# STM32U3C5xx register map
File version: 1.0
Registers are 32-bit, read-write, reset 0x0 unless marked. A register's access mark holds for its fields unless they carry their own. Offsets are from the block's base; [hi:lo] are bit positions; 'fields as' and 'values as' point back to an identical list.

## RCC — Reset and Clock Control
Base 0x40030C00
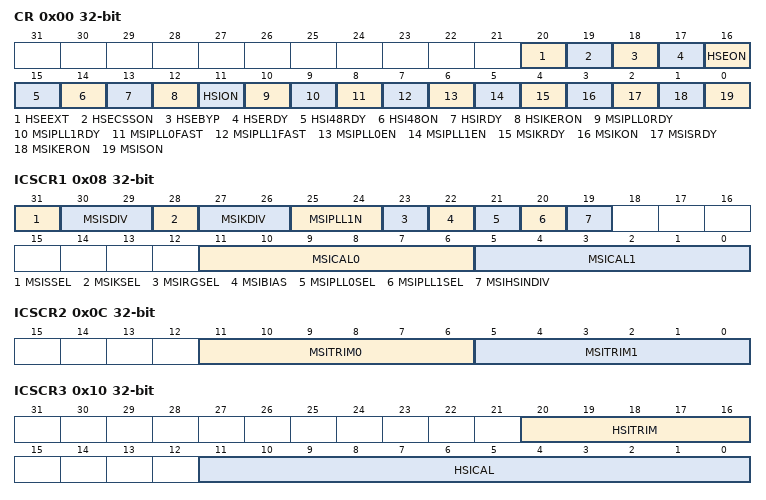
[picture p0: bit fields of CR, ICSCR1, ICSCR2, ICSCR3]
0x00 CR — RCC Clock Control Register
  [20] HSEEXT — External High Speed Oscillator (HSE) External Clock Bypass Mode
    0=ANALOG_MODE; 1=DIGITAL_MODE
  [19] HSECSSON — External High Speed Oscillator (HSE) Clock Security System Enable
  [18] HSEBYP — External High Speed Oscillator (HSE) Crystal Oscillator Bypass
  [17] HSERDY — External High Speed Oscillator (HSE) Clock Ready
  [16] HSEON — External High Speed Oscillator (HSE) Clock Enable
  [15] HSI48RDY — Internal High Speed Oscillator (HSI48) Clock Ready Flag
  [14] HSI48ON — Internal High Speed Oscillator (HSI48) Clock Enable
  [13] HSIRDY — Internal High Speed Oscillator (HSI16) Clock Ready Flag
  [12] HSIKERON — Internal High Speed Oscillator (HSI16) Clock Enable for some peripheral Kernels
  [11] HSION — Internal High Speed Oscillator (HSI16) Clock Enable
  [10] MSIPLL0RDY — MSIRC0 PLL-mode ready flag
  [9] MSIPLL1RDY — MSIRC1 PLL-mode ready flag
  [8] MSIPLL0FAST — MSIRC0 PLL-mode fast startup
    0=NORMAL (MSIRC0 PLL mode normal startup); 1=FAST (MSIRC0 PLL mode fast startup)
  [7] MSIPLL1FAST — MSIRC1 PLL-mode fast startup
    0=NORMAL (MSIRC1 PLL mode normal startup); 1=FAST (MSIRC1 PLL mode fast startup)
  [6] MSIPLL0EN — MSIRC0 PLL-mode enable
  [5] MSIPLL1EN — MSIRC1 PLL-mode enable
  [4] MSIKRDY — Internal Multi Speed Oscillator Kernel (MSIK) Ready Flag
  [3] MSIKON — Internal Multi Speed Oscillator Kernel (MSIK) Enable
  [2] MSISRDY — Internal Multi Speed Oscillator System (MSIS) Clock Ready Flag
  [1] MSIKERON — MSI Enable for some peripheral Kernels
  [0] MSISON — Internal Multi Speed Oscillator System (MSIS) Clock Enable
0x08 ICSCR1 — RCC Internal Clock Sources Calibration Register 1
  [31] MSISSEL — MSIS clock source selection
    0=RC0 (MSIRC0 (96 MHz) is selected as source to generate MSISSRANGE); 1=RC1 (MSIRC1 (24 MHz) is selected as source to generate MSISSRANGE)
  [30:29] MSISDIV — MSIS Oscillator division
    0=DIV_1 (MSIRCx /1 is selected for MSIS (RC0 : range 0 around 96 MHz / RC1 : range 4 around 24 MHz)); 1=DIV_2 (MSIRCx /2 is selected for MSIS (RC0 : range 0 around 48 MHz / RC1 : range 4 around 12 MHz)); 2=DIV_4 (MSIRCx /4 is selected for MSIS (RC0 : range 0 around 24 MHz / RC1 : range 4 around 6 MHz)); 3=DIV_8 (MSIRCx /8 is selected for MSIS (RC0 : range 0 around 12 MHz / RC1 : range 4 around 3 MHz))
  [28] MSIKSEL — MSIK clock source selection
    0=RC0 (MSIRC0 (96 MHz) is selected as source to generate MSIKSRANGE); 1=RC1 (MSIRC1 (24 MHz) is selected as source to generate MSIKSRANGE)
  [27:26] MSIKDIV — MSIK Oscillator division
    0=DIV_1 (MSIRCx /1 is selected for MSIK (RC0 : range 0 around 96 MHz / RC1 : range 4 around 24 MHz)); 1=DIV_2 (MSIRCx /2 is selected for MSIK (RC0 : range 0 around 48 MHz / RC1 : range 4 around 12 MHz)); 2=DIV_4 (MSIRCx /4 is selected for MSIK (RC0 : range 0 around 24 MHz / RC1 : range 4 around 6 MHz)); 3=DIV_8 (MSIRCx /8 is selected for MSIK (RC0 : range 0 around 12 MHz / RC1 : range 4 around 3 MHz))
  [25:24] MSIPLL1N — MSIPLL1N[1:0] bits: MSIRC1 frequency selection in PLL-mode
    0=MULT_732 (Freq MSIRC1 = 23.9862 MHz); 2=MULT_689 (Freq MSIRC1 = 22.5772 MHz); 3=MULT_750 (Freq MSIRC1 = 24.576 MHz)
  [23] MSIRGSEL — MSI clock range selection
    0=MSIXDIVS (MSIS/MSIK ranges provided by MSISSRANGE[3:0] and MSIKSRANGE[3:0] in RCC_CSR); 1=MSIXDIV (MSIS/MSIK ranges provided by MSISRANGE[3:0] and MSIKRANGE[3:0] in RCC_ICSCR1)
  [22] MSIBIAS — MSI BIAS mode selection
    0=CONTINUOUS (MSI bias continuous mode (clock accuracy fast settling time)); 1=SAMPLING (MSI bias sampling mode when the device is in Stop 1 or Stop 2 (ultra-low-power mode))
  [21] MSIPLL0SEL — MSIRC0 PLL-mode input clock Selection
    0=LSE (LSE is used as MSIRC0 input clock when PLL-mode is selected); 1=HSE_OR_HSEDIV2 (HSE or HSE/2 is used as MSIRC0 input clock when PLL-mode is selected)
  [20] MSIPLL1SEL — MSIRC1 PLL-mode input clock Selection
    0=LSE (LSE is used as MSIRC1 input clock when PLL-mode is selected); 1=HSE_OR_HSEDIV2 (HSE or HSE/2 is used as MSIRC1 input clock when PLL-mode is selected)
  [19] MSIHSINDIV — MSIRCx PLL-mode HSE input fast clock Division
    0=HSE (HSE (16 MHz) is used as MSI input clock when PLL-mode with high-speed clock is selected); 1=DIV_2 (HSE (32 MHz) /2 is used as MSI input clock when PLL-mode with high-speed clock is selected)
  [11:6] MSICAL0 — MSICAL0[5:0] bits: MSIRC0 clock Calibration
  [5:0] MSICAL1 — MSICAL1[5:0] bits: MSIRC1 clock Calibration
0x0C ICSCR2 — RCC Internal Clock Sources Calibration Register 2
  [11:6] MSITRIM0 — MSITRIM0[5:0] bits: MSIRC0 clock trimming
  [5:0] MSITRIM1 — MSITRIM1[5:0] bits: MSIRC1 clock trimming
0x10 ICSCR3 — RCC Internal Clock Sources Calibration Register 3
  [20:16] HSITRIM — HSITRIM[4:0] bits: HSI clock trimming
  [11:0] HSICAL — HSICAL[11:0] bits: HSI clock calibration
0x14 CRRCR — RCC Clock Recovery RC Register
  [8:0] HSI48CAL — HSI48CAL[8:0] bits: HSI48 Clock Calibration
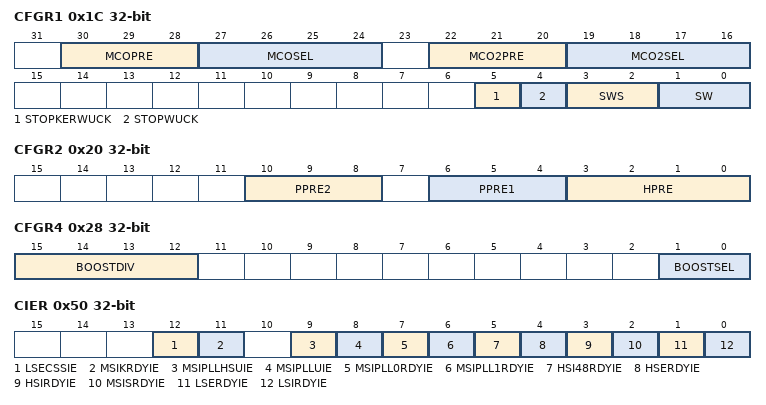
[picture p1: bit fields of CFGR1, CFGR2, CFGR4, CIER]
0x1C CFGR1 — RCC Clock Configuration Register 1
  [30:28] MCOPRE — MCOPRE [2:0] bits : Microcontroller Clock Output (MCO) Prescaler
    0=DIV_1 (MCO not divided); 1=DIV_2 (MCO divided by 2); 2=DIV_4 (MCO divided by 4); 3=DIV_8 (MCO divided by 8); 4=DIV_16 (MCO divided by 16); 5=DIV_32 (MCO divided by 32); 6=DIV_64 (MCO divided by 64); 7=DIV_128 (MCO divided by 128)
  [27:24] MCOSEL — MCOSEL [3:0] bits : Microcontroller Clock Output (MCO) Selection
    0=NOCLOCK (MCO output disabled, no clock on MCO); 1=SYSCLK (SYSCLK selection as MCO source); 2=MSIS (MSIS selection as MCO source); 3=HSI16 (HSI16 selection as MCO source); 4=HSE (HSE selection as MCO source); 5=LSI (LSI selection as MCO source); 6=LSE (LSE selection as MCO source); 7=HSI48 (HSI48 selection as MCO source); 8=MSIK (MSIK selection as MCO source)
  [22:20] MCO2PRE — MCO2PRE [2:0] bits : Microcontroller Clock Output 2 (MCO2) Prescaler
    0=DIV_1 (MCO2 not divided); 1=DIV_2 (MCO2 divided by 2); 2=DIV_4 (MCO2 divided by 4); 3=DIV_8 (MCO2 divided by 8); 4=DIV_16 (MCO2 divided by 16); 5=DIV_32 (MCO2 divided by 32); 6=DIV_64 (MCO2 divided by 64); 7=DIV_128 (MCO2 divided by 128)
  [19:16] MCO2SEL — MCO2SEL [3:0] bits : Microcontroller Clock Output 2 (MCO2) Selection
    0=NOCLOCK (MCO2 output disabled, no clock on MCO2); 1=SYSCLK (SYSCLK selection as MCO2 source); 2=MSIS (MSIS selection as MCO2 source); 3=HSI16 (HSI16 selection as MCO2 source); 4=HSE (HSE selection as MCO2 source); 5=LSI (LSI selection as MCO2 source); 6=LSE (LSE selection as MCO2 source); 7=HSI48 (HSI48 selection as MCO2 source); 8=MSIK (MSIK selection as MCO2 source)
  [5] STOPKERWUCK — Wakeup from Stop kernel clock automatic enable selection
    0=MSIK (MSIK oscillator selected as wakeup from stop kernel clock); 1=HSI16 (HSI16 oscillator selected as wakeup from stop kernel clock)
  [4] STOPWUCK — Wake Up from stop and CSS backup clock selection
    0=MSIS (MSIS oscillator selected as wakeup from stop clock and CSS backup clock); 1=HSI16 (HSI16 oscillator selected as wakeup from stop clock and CSS backup clock)
  [3:2] SWS — SWS[1:0] bits : System Clock Switch Status
  [1:0] SW — SW[1:0] bits : System clock Switch
    0=MSIS (MSIS selection as system clock); 1=HSI16 (HSI16 selection as system clock); 2=HSE (HSE selection as system clock)
0x20 CFGR2 — RCC Clock Configuration Register 2
  [10:8] PPRE2 — PPRE2[2:0] bits : APB2 prescaler
    0=DIV_1 (HCLK not divided); 4=DIV_2 (HCLK divided by 2); 5=DIV_4 (HCLK divided by 4); 6=DIV_8 (HCLK divided by 8); 7=DIV_16 (HCLK divided by 16)
  [6:4] PPRE1 — PPRE1[2:0] bits : APB1 prescaler
    values as PPRE2
  [3:0] HPRE — HPRE[3:0] bits : AHB prescaler
    0=DIV_1 (SYSCLK not divided); 8=DIV_2 (SYSCLK divided by 2); 9=DIV_4 (SYSCLK divided by 4); 10=DIV_8 (SYSCLK divided by 8); 11=DIV_16 (SYSCLK divided by 16); 12=DIV_64 (SYSCLK divided by 64); 13=DIV_128 (SYSCLK divided by 128); 14=DIV_256 (SYSCLK divided by 256); 15=DIV_512 (SYSCLK divided by 512)
0x24 CFGR3 — RCC Clock Configuration Register 3
  [6:4] PPRE3 — PPRE3[2:0] bits : APB3 prescaler
    values as CFGR2.PPRE2
0x28 CFGR4 — RCC Clock Configuration Register 4
  [15:12] BOOSTDIV — BOOSTDIV[3:0] bits : EPOD booster input clock prescaler
    0=EPODBOOSTCLKPRESCAL_1; 1=EPODBOOSTCLKPRESCAL_2; 2=EPODBOOSTCLKPRESCAL_4; 3=EPODBOOSTCLKPRESCAL_6; 4=EPODBOOSTCLKPRESCAL_8; 5=EPODBOOSTCLKPRESCAL_10; 6=EPODBOOSTCLKPRESCAL_12; 7=EPODBOOSTCLKPRESCAL_14; 8=EPODBOOSTCLKPRESCAL_16
  [1:0] BOOSTSEL — BOOSTSEL[1:0] bits : EPOD booster input clock source selection
    0=BYPASS; 1=MSIS; 2=HSI16; 3=HSE
0x50 CIER — Clock Interrupt Enable Register
  [12] LSECSSIE — LSE Clock Security System Interrupt Enable
  [11] MSIKRDYIE — MSIK Ready Interrupt Enable
  [9] MSIPLLHSUIE — MSI PLL-mode with HSE unlock Interrupt Enable
  [8] MSIPLLUIE — MSI PLL-mode with LSE unlock Interrupt Enable
  [7] MSIPLL0RDYIE — MSIRC0 PLL-mode Ready Interrupt Enable
  [6] MSIPLL1RDYIE — MSIRC1 PLL-mode Ready Interrupt Enable
  [5] HSI48RDYIE — HSI48 Ready Interrupt Enable
  [4] HSERDYIE — HSE Ready Interrupt Enable
  [3] HSIRDYIE — HSI16 Ready Interrupt Enable
  [2] MSISRDYIE — MSIS Ready Interrupt Enable
  [1] LSERDYIE — LSE Ready Interrupt Enable
  [0] LSIRDYIE — LSI Ready Interrupt Enable
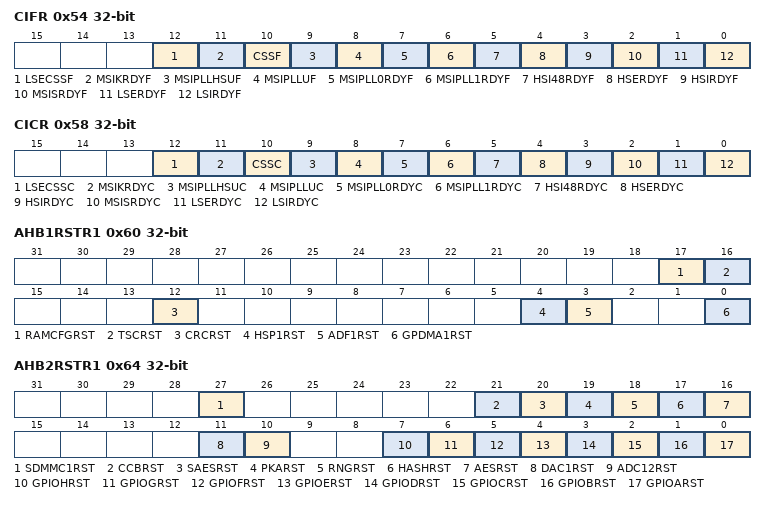
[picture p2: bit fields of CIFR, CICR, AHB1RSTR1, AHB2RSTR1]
0x54 CIFR — Clock Interrupt Flag Register
  [12] LSECSSF — LSF Clock Security System Interrupt Flag
  [11] MSIKRDYF — MSIK Ready Interrupt Flag
  [10] CSSF — HSE Clock Security System Interrupt flag
  [9] MSIPLLHSUF — MSI PLL-mode with LSE unlock Interrupt Flag
  [8] MSIPLLUF — MSI PLL-mode with HSE unlock Interrupt Flag
  [7] MSIPLL0RDYF — MSIRC0 PLL-mode Ready Interrupt Flag
  [6] MSIPLL1RDYF — MSIRC1 PLL-mode Ready Interrupt Flag
  [5] HSI48RDYF — HSI48 Ready Interrupt Flag
  [4] HSERDYF — HSF Ready Interrupt Flag
  [3] HSIRDYF — HSI16 Ready Interrupt Flag
  [2] MSISRDYF — MSIS Ready Interrupt Flag
  [1] LSERDYF — LSF Ready Interrupt Flag
  [0] LSIRDYF — LSI Ready Interrupt Flag
0x58 CICR — Clock Interrupt Clear Register
  [12] LSECSSC — LSE Clock Security System Interrupt Clear
  [11] MSIKRDYC — MSIK Ready Interrupt Clear
  [10] CSSC — HSE Clock Security System Interrupt flag
  [9] MSIPLLHSUC — MSI PLL-mode with LSE unlock Interrupt Clear
  [8] MSIPLLUC — MSI PLL-mode with HSE unlock Interrupt Clear
  [7] MSIPLL0RDYC — MSIRC0 PLL-mode Ready Interrupt Clear
  [6] MSIPLL1RDYC — MSIRC1 PLL-mode Ready Interrupt Clear
  [5] HSI48RDYC — HSI48 Ready Interrupt Clear
  [4] HSERDYC — HSC Ready Interrupt Clear
  [3] HSIRDYC — HSI16 Ready Interrupt Clear
  [2] MSISRDYC — MSIS Ready Interrupt Clear
  [1] LSERDYC — LSC Ready Interrupt Clear
  [0] LSIRDYC — LSI Ready Interrupt Clear
0x60 AHB1RSTR1 — AHB1 Peripherals Reset Register 1
  [17] RAMCFGRST — RAMCFG Reset
  [16] TSCRST — TSC Reset
  [12] CRCRST — CRC Reset
  [4] HSP1RST — HSP1 Reset
  [3] ADF1RST — ADF1 Reset
  [0] GPDMA1RST — GPDMA1 Reset
0x64 AHB2RSTR1 — AHB2 Peripherals Reset Register 1
  [27] SDMMC1RST — SDMMC1 Reset
  [21] CCBRST — CCB Reset
  [20] SAESRST — SAES Reset
  [19] PKARST — PKA reset
  [18] RNGRST — RNG Reset
  [17] HASHRST — Hash Reset
  [16] AESRST — AES Reset
  [11] DAC1RST — DAC1 Reset
  [10] ADC12RST — ADC12 Reset
  [7] GPIOHRST — IO port H Reset
  [6] GPIOGRST — IO port G Reset
  [5] GPIOFRST — IO port F Reset
  [4] GPIOERST — IO port E Reset
  [3] GPIODRST — IO port D Reset
  [2] GPIOCRST — IO port C Reset
  [1] GPIOBRST — IO port B Reset
  [0] GPIOARST — IO port A Reset
0x68 AHB2RSTR2 — AHB2 Peripherals Reset Register 2
  [4] OCTOSPI1RST — OCTOSPI1 Reset
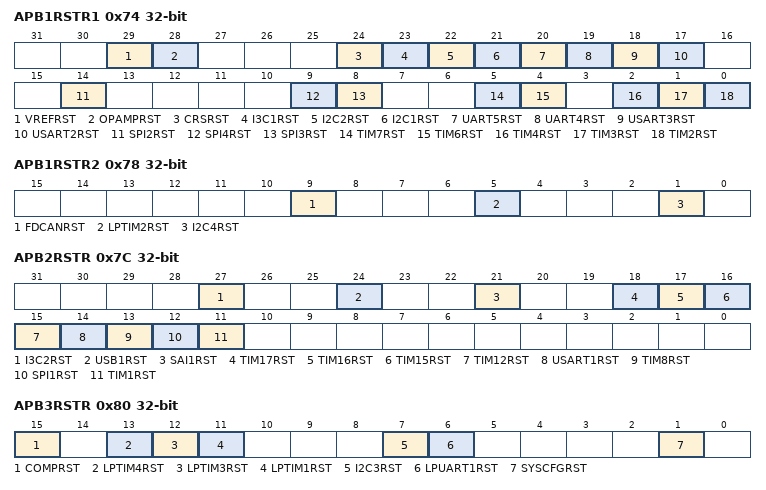
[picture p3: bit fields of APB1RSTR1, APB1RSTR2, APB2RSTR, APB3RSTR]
0x74 APB1RSTR1 — APB1 Peripherals Reset Register 1
  [29] VREFRST — VREFBUF Reset
  [28] OPAMPRST — OPAMP Reset
  [24] CRSRST — CRS Reset
  [23] I3C1RST — I3C1 Reset
  [22] I2C2RST — I2C2 Reset
  [21] I2C1RST — I2C1 Reset
  [20] UART5RST — UART5 Reset
  [19] UART4RST — UART4 Reset
  [18] USART3RST — USART3 Reset
  [17] USART2RST — USART2 Reset
  [14] SPI2RST — SPI2 Reset
  [9] SPI4RST — SPI4 Reset
  [8] SPI3RST — SPI3 Reset
  [5] TIM7RST — TIM7 Reset
  [4] TIM6RST — TIM6 Reset
  [2] TIM4RST — TIM4 Reset
  [1] TIM3RST — TIM3 Reset
  [0] TIM2RST — TIM2 Reset
0x78 APB1RSTR2 — APB1 Peripherals Reset Register 2
  [9] FDCANRST — FDCAN1 and FDCAN2 Reset
  [5] LPTIM2RST — LPTIM2 Reset
  [1] I2C4RST — I2C4 Reset
0x7C APB2RSTR — APB2 Peripherals Reset Register
  [27] I3C2RST — I3C2 Reset
  [24] USB1RST — USB1 Reset
  [21] SAI1RST — SAI1 Reset
  [18] TIM17RST — TIM17 Reset
  [17] TIM16RST — TIM16 Reset
  [16] TIM15RST — TIM15 Reset
  [15] TIM12RST — TIM12 Reset
  [14] USART1RST — USART1 Reset
  [13] TIM8RST — TIM8 Reset
  [12] SPI1RST — SPI1 Reset
  [11] TIM1RST — TIM1 Reset
0x80 APB3RSTR — APB3 Peripherals Reset Register
  [15] COMPRST — COMP Reset
  [13] LPTIM4RST — LPTIM4 Reset
  [12] LPTIM3RST — LPTIM3 Reset
  [11] LPTIM1RST — LPTIM1 Reset
  [7] I2C3RST — I2C3 Reset
  [6] LPUART1RST — LPUART1 Reset
  [1] SYSCFGRST — SYSCFG Reset
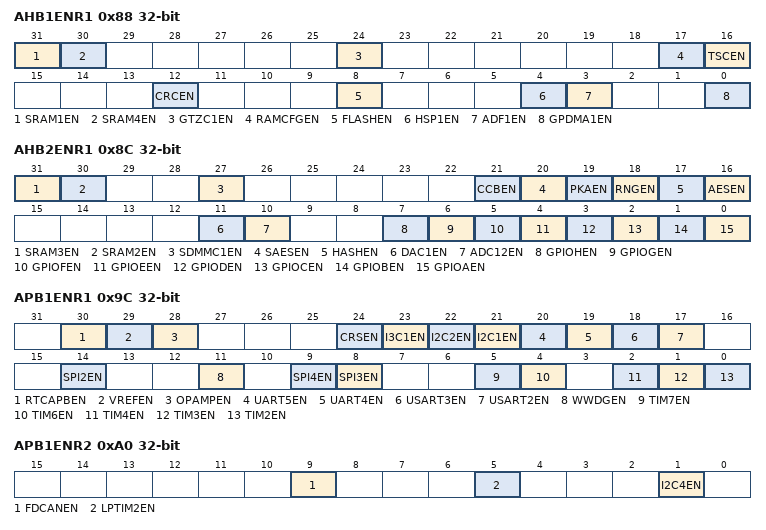
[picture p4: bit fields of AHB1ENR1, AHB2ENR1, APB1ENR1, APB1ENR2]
0x88 AHB1ENR1 — AHB1 Peripherals Clock Enable Register 1
  [31] SRAM1EN — SRAM1 Enable
  [30] SRAM4EN — SRAM4 Enable
  [24] GTZC1EN — GTZC1 Enable
  [17] RAMCFGEN — RAMCFG Enable
  [16] TSCEN — TSC Enable
  [12] CRCEN — CRC Enable
  [8] FLASHEN — FLASH Enable
  [4] HSP1EN — HSP1 Enable
  [3] ADF1EN — ADF1 Enable
  [0] GPDMA1EN — GPDMA1 Enable
0x8C AHB2ENR1 — AHB2 Peripherals Clock Enable Register 1
  [31] SRAM3EN — SRAM3 Enable
  [30] SRAM2EN — SRAM2 Enable
  [27] SDMMC1EN — SDMMC1 Enable
  [21] CCBEN — CCB Enable
  [20] SAESEN — SAES Enable
  [19] PKAEN — PKA Enable
  [18] RNGEN — RNG Enable
  [17] HASHEN — HASH Enable
  [16] AESEN — AES Enable
  [11] DAC1EN — DAC1 Enable
  [10] ADC12EN — ADC12 Enable
  [7] GPIOHEN — IO port H Enable
  [6] GPIOGEN — IO port G Enable
  [5] GPIOFEN — IO port F Enable
  [4] GPIOEEN — IO port E Enable
  [3] GPIODEN — IO port D Enable
  [2] GPIOCEN — IO port C Enable
  [1] GPIOBEN — IO port B Enable
  [0] GPIOAEN — IO port A Enable
0x90 AHB2ENR2 — AHB2 Peripherals Clock Enable Register 2
  [4] OCTOSPI1EN — OCTOSPI1 Enable
0x94 AHB1ENR2 — AHB1 Peripherals Clock Enable Register 2
  [2] PWREN — PWR Enable
0x9C APB1ENR1 — APB1 Peripherals Clock Enable Register 1
  [30] RTCAPBEN — RTCAPB Enable
  [29] VREFEN — VREFBUF Enable
  [28] OPAMPEN — OPAMP Enable
  [24] CRSEN — CRS Enable
  [23] I3C1EN — I3C1 Enable
  [22] I2C2EN — I2C2 Enable
  [21] I2C1EN — I2C1 Enable
  [20] UART5EN — UART5 Enable
  [19] UART4EN — UART4 Enable
  [18] USART3EN — USART3 Enable
  [17] USART2EN — USART2 Enable
  [14] SPI2EN — SPI2 Enable
  [11] WWDGEN — WWDG Enable
  [9] SPI4EN — SPI4 Enable
  [8] SPI3EN — SPI3 Enable
  [5] TIM7EN — TIM7 Enable
  [4] TIM6EN — TIM6 Enable
  [2] TIM4EN — TIM4 Enable
  [1] TIM3EN — TIM3 Enable
  [0] TIM2EN — TIM2 Enable
0xA0 APB1ENR2 — APB1 Peripherals Clock Enable Register 2
  [9] FDCANEN — FDCAN1 and FDCAN2 Enable
  [5] LPTIM2EN — LPTIM2 Enable
  [1] I2C4EN — I2C4 Enable
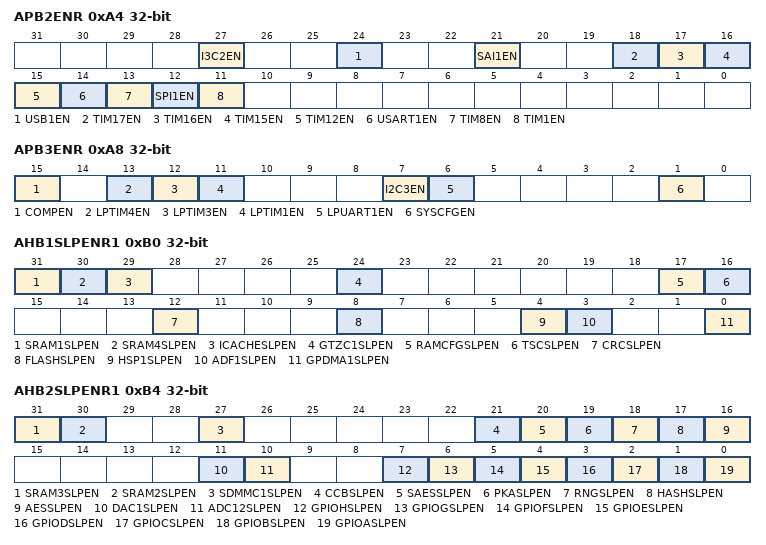
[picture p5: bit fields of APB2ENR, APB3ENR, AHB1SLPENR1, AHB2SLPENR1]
0xA4 APB2ENR — APB2 Peripherals Clock Enable Register
  [27] I3C2EN — I3C2 Enable
  [24] USB1EN — USB1 Enable
  [21] SAI1EN — SAI1 Enable
  [18] TIM17EN — TIM17 Enable
  [17] TIM16EN — TIM16 Enable
  [16] TIM15EN — TIM15 Enable
  [15] TIM12EN — TIM12 Enable
  [14] USART1EN — USART1 Enable
  [13] TIM8EN — TIM8 Enable
  [12] SPI1EN — SPI1 Enable
  [11] TIM1EN — TIM1 Enable
0xA8 APB3ENR — APB3 Peripherals Clock Enable Register
  [15] COMPEN — COMP Enable
  [13] LPTIM4EN — LPTIM4 Enable
  [12] LPTIM3EN — LPTIM3 Enable
  [11] LPTIM1EN — LPTIM1 Enable
  [7] I2C3EN — I2C3 Enable
  [6] LPUART1EN — LPUART1 Enable
  [1] SYSCFGEN — SYSCFG Enable
0xB0 AHB1SLPENR1 — AHB1 Peripherals Clock Enable in Sleep Mode Register 1
  [31] SRAM1SLPEN — SRAM1 Sleep Mode Enable
  [30] SRAM4SLPEN — SRAM4 Sleep Mode Enable
  [29] ICACHESLPEN — ICACHE Sleep Mode Enable
  [24] GTZC1SLPEN — GTZC1 Sleep Mode Enable
  [17] RAMCFGSLPEN — RAMCFG Sleep Mode Enable
  [16] TSCSLPEN — Touch SSLPENsing Controller Sleep Mode Enable
  [12] CRCSLPEN — CRC Sleep Mode Enable
  [8] FLASHSLPEN — FLASH Sleep Mode Enable
  [4] HSP1SLPEN — HSP1 Sleep Mode Enable
  [3] ADF1SLPEN — ADF1 Sleep Mode Enable
  [0] GPDMA1SLPEN — GPDMA1 Sleep Mode Enable
0xB4 AHB2SLPENR1 — AHB2 Peripherals Clock Enable in Sleep Mode Register 1
  [31] SRAM3SLPEN — SRAM3 Sleep Mode Enable
  [30] SRAM2SLPEN — SRAM2 Sleep Mode Enable
  [27] SDMMC1SLPEN — SDMMC1 Sleep Mode Enable
  [21] CCBSLPEN — CCB Sleep Mode Enable
  [20] SAESSLPEN — SAES Sleep Mode Enable
  [19] PKASLPEN — PKA Sleep Mode Enable
  [18] RNGSLPEN — RNG Sleep Mode Enable
  [17] HASHSLPEN — HASH Sleep Mode Enable
  [16] AESSLPEN — AES Sleep Mode Enable
  [11] DAC1SLPEN — DAC1 Sleep Mode Enable
  [10] ADC12SLPEN — ADC12 Sleep Mode Enable
  [7] GPIOHSLPEN — IO port H Sleep Mode Enable
  [6] GPIOGSLPEN — IO port G Sleep Mode Enable
  [5] GPIOFSLPEN — IO port F Sleep Mode Enable
  [4] GPIOESLPEN — IO port E Sleep Mode Enable
  [3] GPIODSLPEN — IO port D Sleep Mode Enable
  [2] GPIOCSLPEN — IO port C Sleep Mode Enable
  [1] GPIOBSLPEN — IO port B Sleep Mode Enable
  [0] GPIOASLPEN — IO port A Sleep Mode Enable
0xB8 AHB2SLPENR2 — AHB2 Peripherals Clock Enable in Sleep Mode Register 2
  [4] OCTOSPI1SLPEN — OCTOSPI1 Sleep Mode Enable
0xBC AHB1SLPENR2 — AHB1 Peripherals Clock Enable in Sleep Mode Register 2
  [2] PWRSLPEN — PWR Sleep Mode Enable
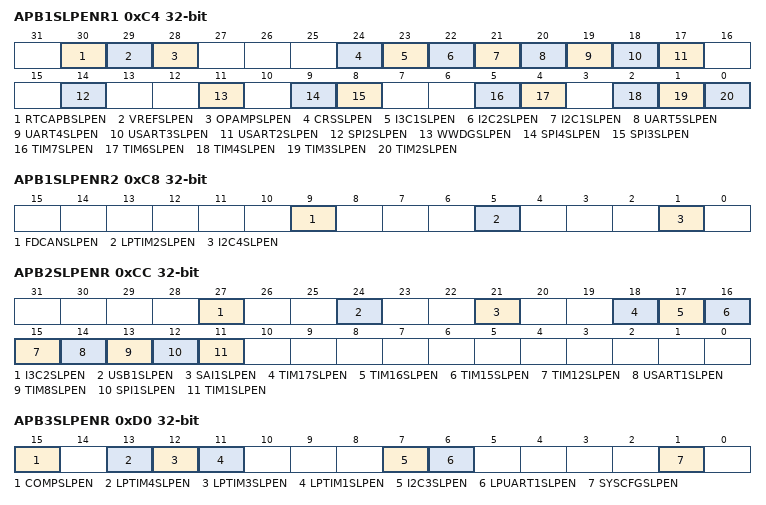
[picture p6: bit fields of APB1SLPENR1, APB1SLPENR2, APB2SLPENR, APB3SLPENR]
0xC4 APB1SLPENR1 — APB1 Peripherals Clock Enable in Sleep Mode Register 1
  [30] RTCAPBSLPEN — RTCAPB Sleep Mode Enable
  [29] VREFSLPEN — VREFBUF Sleep Mode Enable
  [28] OPAMPSLPEN — OPAMP Sleep Mode Enable
  [24] CRSSLPEN — CRS Sleep Mode Enable
  [23] I3C1SLPEN — I3C1 Sleep Mode Enable
  [22] I2C2SLPEN — I2C2 Sleep Mode Enable
  [21] I2C1SLPEN — I2C1 Sleep Mode Enable
  [20] UART5SLPEN — UART5 Sleep Mode Enable
  [19] UART4SLPEN — UART4 Sleep Mode Enable
  [18] USART3SLPEN — USART3 Sleep Mode Enable
  [17] USART2SLPEN — USART2 Sleep Mode Enable
  [14] SPI2SLPEN — SPI2 Sleep Mode Enable
  [11] WWDGSLPEN — WWDG Sleep Mode Enable
  [9] SPI4SLPEN — SPI4 Sleep Mode Enable
  [8] SPI3SLPEN — SPI3 Sleep Mode Enable
  [5] TIM7SLPEN — TIM7 Sleep Mode Enable
  [4] TIM6SLPEN — TIM6 Sleep Mode Enable
  [2] TIM4SLPEN — TIM4 Sleep Mode Enable
  [1] TIM3SLPEN — TIM3 Sleep Mode Enable
  [0] TIM2SLPEN — TIM2 Sleep Mode Enable
0xC8 APB1SLPENR2 — APB1 Peripherals Clock Enable in Sleep Mode Register 2
  [9] FDCANSLPEN — FDCAN1 and FDCAN2 Sleep Mode Enable
  [5] LPTIM2SLPEN — LPTIM2 Sleep Mode Enable
  [1] I2C4SLPEN — I2C4 Sleep Mode Enable
0xCC APB2SLPENR — APB2 Peripherals Clock Enable in Sleep Mode Register
  [27] I3C2SLPEN — I3C2 Sleep Mode Enable
  [24] USB1SLPEN — USB1 Sleep Mode Enable
  [21] SAI1SLPEN — SAI1 Sleep Mode Enable
  [18] TIM17SLPEN — TIM17 Sleep Mode Enable
  [17] TIM16SLPEN — TIM16 Sleep Mode Enable
  [16] TIM15SLPEN — TIM15 Sleep Mode Enable
  [15] TIM12SLPEN — TIM12 Sleep Mode Enable
  [14] USART1SLPEN — USART1 Sleep Mode Enable
  [13] TIM8SLPEN — TIM8 Sleep Mode Enable
  [12] SPI1SLPEN — SPI1 Sleep Mode Enable
  [11] TIM1SLPEN — TIM1 Sleep Mode Enable
0xD0 APB3SLPENR — APB3 Peripherals Clock Enable in Sleep Mode Register
  [15] COMPSLPEN — COMP Sleep Mode Enable
  [13] LPTIM4SLPEN — LPTIM4 Sleep Mode Enable
  [12] LPTIM3SLPEN — LPTIM3 Sleep Mode Enable
  [11] LPTIM1SLPEN — LPTIM1 Sleep Mode Enable
  [7] I2C3SLPEN — I2C3 Sleep Mode Enable
  [6] LPUART1SLPEN — LPUART1 Sleep Mode Enable
  [1] SYSCFGSLPEN — SYSCFG Sleep Mode Enable
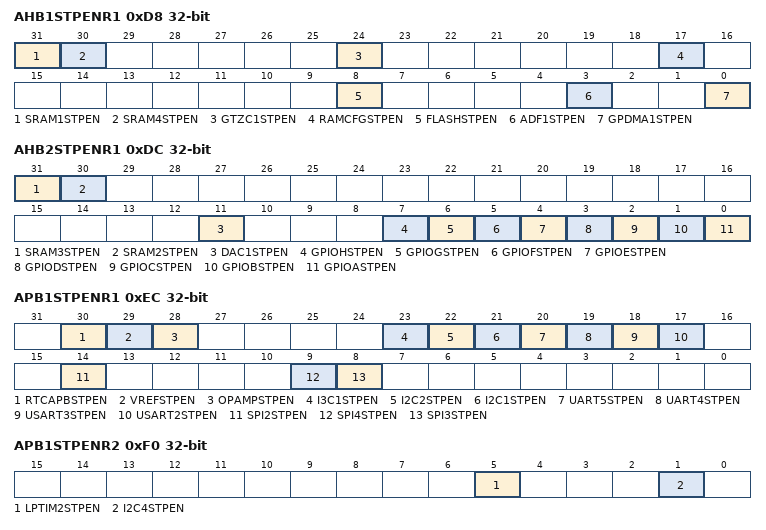
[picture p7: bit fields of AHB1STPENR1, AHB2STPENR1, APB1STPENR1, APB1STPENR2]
0xD8 AHB1STPENR1 — AHB1 Peripherals Clock Enable in Stop Mode Register 1
  [31] SRAM1STPEN — SRAM1 Clock Enable in Stop Mode
  [30] SRAM4STPEN — SRAM4 Clock Enable in Stop Mode
  [24] GTZC1STPEN — GTZC1 Clock Enable in Stop Mode
  [17] RAMCFGSTPEN — RAMCFG Clock Enable in Stop Mode
  [8] FLASHSTPEN — FLASH Clock Enable in Stop Mode
  [3] ADF1STPEN — ADF1 Clock Enable in Stop Mode
  [0] GPDMA1STPEN — GPDMA1 Clock Enable in Stop Mode
0xDC AHB2STPENR1 — AHB2 Peripherals Clock Enable in Stop Mode Register 1
  [31] SRAM3STPEN — SRAM3 Clock Enable in Stop Mode
  [30] SRAM2STPEN — SRAM2 Clock Enable in Stop Mode
  [11] DAC1STPEN — DAC1 Clock Enable in Stop Mode
  [7] GPIOHSTPEN — IO port H Clock Enable in Stop Mode
  [6] GPIOGSTPEN — IO port G Clock Enable in Stop Mode
  [5] GPIOFSTPEN — IO port F Clock Enable in Stop Mode
  [4] GPIOESTPEN — IO port E Clock Enable in Stop Mode
  [3] GPIODSTPEN — IO port D Clock Enable in Stop Mode
  [2] GPIOCSTPEN — IO port C Clock Enable in Stop Mode
  [1] GPIOBSTPEN — IO port B Clock Enable in Stop Mode
  [0] GPIOASTPEN — IO port A Clock Enable in Stop Mode
0xEC APB1STPENR1 — APB1 Peripherals Clock Enable in Stop Mode Register 1
  [30] RTCAPBSTPEN — RTCAPB Clock Enable in Stop Mode
  [29] VREFSTPEN — VREFBUF Clock Enable in Stop Mode
  [28] OPAMPSTPEN — OPAMP Clock Enable in Stop Mode
  [23] I3C1STPEN — I3C1 Clock Enable in Stop Mode
  [22] I2C2STPEN — I2C2 Clock Enable in Stop Mode
  [21] I2C1STPEN — I2C1 Clock Enable in Stop Mode
  [20] UART5STPEN — UART5 Clock Enable in Stop Mode
  [19] UART4STPEN — UART4 Clock Enable in Stop Mode
  [18] USART3STPEN — USART3 Clock Enable in Stop Mode
  [17] USART2STPEN — USART2 Clock Enable in Stop Mode
  [14] SPI2STPEN — SPI2 Clock Enable in Stop Mode
  [9] SPI4STPEN — SPI4 Clock Enable in Stop Mode
  [8] SPI3STPEN — SPI3 Clock Enable in Stop Mode
0xF0 APB1STPENR2 — APB1 Peripherals Clock Enable in Stop Mode Register 2
  [5] LPTIM2STPEN — LPTIM2 Clock Enable in Stop Mode
  [1] I2C4STPEN — I2C4 Clock Enable in Stop Mode
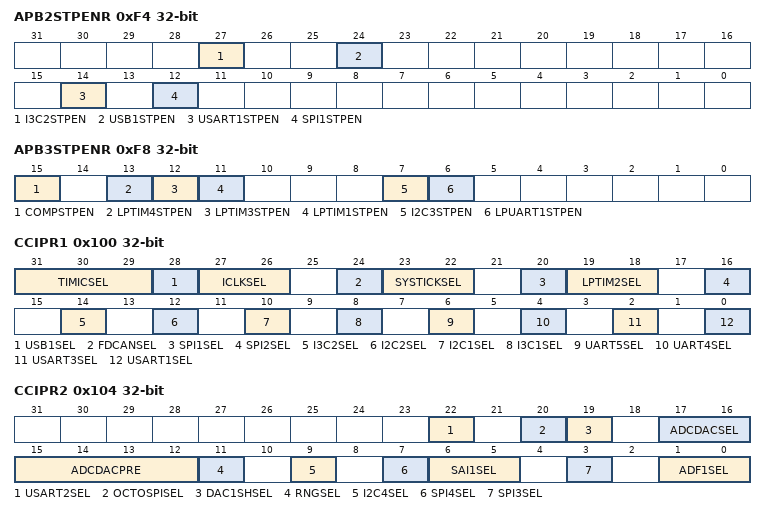
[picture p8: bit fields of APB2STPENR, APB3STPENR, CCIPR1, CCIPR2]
0xF4 APB2STPENR — APB2 Peripherals Clock Enable in Stop Mode Register
  [27] I3C2STPEN — I3C2 Clock Enable in Stop Mode
  [24] USB1STPEN — USB1 Clock Enable in Stop Mode
  [14] USART1STPEN — USART1 Clock Enable in Stop Mode
  [12] SPI1STPEN — SPI1 Clock Enable in Stop Mode
0xF8 APB3STPENR — APB3 Peripherals Clock Enable in Stop Mode Register
  [15] COMPSTPEN — COMP Clock Enable in Stop Mode
  [13] LPTIM4STPEN — LPTIM4 Clock Enable in Stop Mode
  [12] LPTIM3STPEN — LPTIM3 Clock Enable in Stop Mode
  [11] LPTIM1STPEN — LPTIM1 Clock Enable in Stop Mode
  [7] I2C3STPEN — I2C3 Clock Enable in Stop Mode
  [6] LPUART1STPEN — LPUART1 Clock Enable in Stop Mode
0x100 CCIPR1 — Peripherals Independent Clocks Configuration Register 1
  [31:29] TIMICSEL — TIMICSEL[2:0]: TIM16, TIM17 and LPTIM2 Internal Input Capture Kernel Clock Source Selection
  [28] USB1SEL — USB1SEL: USB1 Kernel Clock Source Selection
  [27:26] ICLKSEL — ICLKSEL[1:0]: Intermediate Clock Source Selection
  [24] FDCANSEL — FDCANSEL: FDCAN1 and FDCAN2 Kernel Clock Source Selection
  [23:22] SYSTICKSEL — SYSTICKSEL[1:0]: SYSTICK Clock Source Selection
  [20] SPI1SEL — SPI1SEL: SPI1 Kernel Clock Source Selection
  [19:18] LPTIM2SEL — LPTIM2SEL[1:0]: LPTIM2 Kernel Clock Source Selection
  [16] SPI2SEL — SPI2SEL: SPI2 Kernel Clock Source Selection
  [14] I3C2SEL — I3C2SEL: I3C2 Kernel Clock Source Selection
  [12] I2C2SEL — I2C2SEL: I2C2 Kernel Clock Source Selection
  [10] I2C1SEL — I2C1SEL: I2C1 Kernel Clock Source Selection
  [8] I3C1SEL — I3C1SEL: I3C1 Kernel Clock Source Selection
  [6] UART5SEL — UART5SEL: UART5 Kernel Clock Source Selection
  [4] UART4SEL — UART4SEL: UART4 Kernel Clock Source Selection
  [2] USART3SEL — USART3SEL: USART3 Kernel Clock Source Selection
  [0] USART1SEL — USART1SEL: USART1 Kernel Clock Source Selection
0x104 CCIPR2 — Peripherals Independent Clocks Configuration Register 2
  [22] USART2SEL — USART2SEL: USART2 kernel clock source selection
  [20] OCTOSPISEL — OCTOSPISEL: OCTOSPI1 Kernel Clock Source Selection
  [19] DAC1SHSEL — DACSEL: DAC1 Sample and Hold Clock Source Selection
  [17:16] ADCDACSEL — ADCDACSEL[2:0]: ADC1 and DAC1 Kernel Clock Source Selection
  [15:12] ADCDACPRE — ADCDACPRE[3:0]: ADC/DAC prescaler
  [11] RNGSEL — RNGSEL: RNG Kernel Clock Source Selection
  [9] I2C4SEL — I2C4SEL: I2C4 kernel clock source selection
  [7] SPI4SEL — SPI4SEL: SPI4 kernel clock source selection
  [6:5] SAI1SEL — SAI1SEL[1:0]: SAI1 Kernel Clock Source Selection
  [3] SPI3SEL — SPI3SEL: SPI3 Kernel Clock Source Selection
  [1:0] ADF1SEL — ADF1SEL[1:0]: ADF Kernel Clock Source Selection
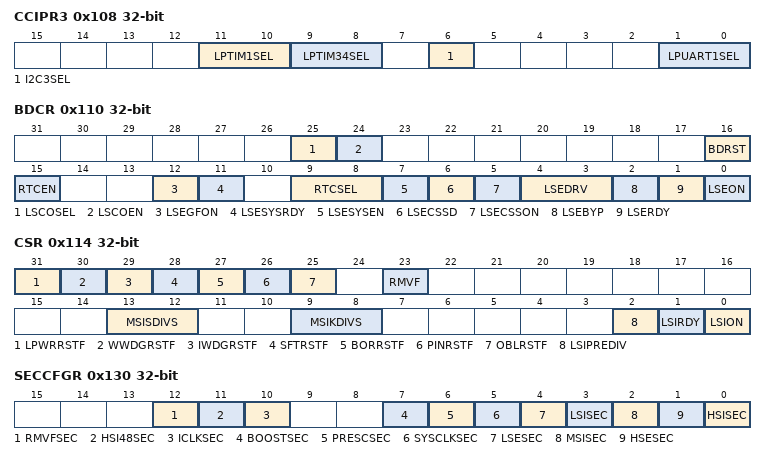
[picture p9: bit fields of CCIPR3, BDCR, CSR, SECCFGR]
0x108 CCIPR3 — Peripherals Independent Clocks Configuration Register 3
  [11:10] LPTIM1SEL — LPTIM1SEL[1:0]: LPTIM1 Kernel Clock Source Selection
  [9:8] LPTIM34SEL — LPTIM34SEL[1:0]: LPTIM3 and LPTIM4 Kernel Clock Source Selection
  [6] I2C3SEL — I2C3SEL: I2C3 Kernel Clock Source Selection
  [1:0] LPUART1SEL — LPUART1SEL[1:0]: LPUART1 Kernel Clock Source Selection
0x110 BDCR — Backup Domain Control Register
  [25] LSCOSEL — Low-speed Clock Output Selection
    0=LSI (LSI selection for low speed clock); 1=LSE (LSE selection for low speed clock)
  [24] LSCOEN — Low-speed Clock Output (LSCO) Enable
  [16] BDRST — BD reset
  [15] RTCEN — RTC Clock Enable
  [12] LSEGFON — LSE Clock Glitch Filter Enable
  [11] LSESYSRDY — LSE System Clock (LSESYS) Ready
  [9:8] RTCSEL — RTCSEL[1:0]: RTC Clock Source Selection
    0=NONE (No clock used as RTC clock); 1=LSE (LSE oscillator clock used as RTC clock); 2=LSI (LSI oscillator clock used as RTC clock); 3=HSE_DIV32 (HSE oscillator clock divided by 32 used as RTC clock)
  [7] LSESYSEN — LSE System Clock (LSESYS) Enable
  [6] LSECSSD — CSS on LSE failure Detection
  [5] LSECSSON — CSS on LSE Enable
  [4:3] LSEDRV — LSEDRV[1:0]: LSE Oscillator Drive Capability
    0=LOW (Xtal mode lower driving capability); 1=MEDIUMLOW (Xtal mode medium low driving capability); 2=MEDIUMHIGH (Xtal mode medium high driving capability); 3=HIGH (Xtal mode higher driving capability)
  [2] LSEBYP — LSE Oscillator Bypass
  [1] LSERDY — LSE Oscillator Ready
  [0] LSEON — LSE Oscillator Enable
0x114 CSR — Control & Status Register
  [31] LPWRRSTF — Low-power Reset Flag
  [30] WWDGRSTF — Window Watchdog Reset Flag
  [29] IWDGRSTF — Independent Watchdog Reset Flag
  [28] SFTRSTF — Software Reset Flag
  [27] BORRSTF — BOR Flag
  [26] PINRSTF — NRST Pin Reset Flag
  [25] OBLRSTF — Option Byte Loader Reset Flag
  [23] RMVF — Remove Reset Flag
  [13:12] MSISDIVS — MSISDIVS[1:0]: MSIS Range After Standby Mode
    1=RANGE_5 (around 12 MHz (reset value)); 2=RANGE_6 (around 6 MHz); 3=RANGE_7 (around 3 MHz)
  [9:8] MSIKDIVS — MSIKDIVS[1:0]: MSIK Range After Standby Mode
    values as MSISDIVS
  [2] LSIPREDIV — LSI clock divider selection
    0=NONE (LSI not divided); 1=PREDIV_128 (LSI divided by 128)
  [1] LSIRDY — LSI Oscillator Ready
  [0] LSION — LSI Oscillator Enable
0x130 SECCFGR — RCC Secure Configuration Register
  [12] RMVFSEC — Remove Reset Flag Security
  [11] HSI48SEC — HSI48 Clock Configuration and Status Bits Security
  [10] ICLKSEC — 48 MHz Clock Source Selection Security
  [7] BOOSTSEC — BOOST Configuration Bits Security
  [6] PRESCSEC — AHBx/APBx Prescaler Configuration Bits Security
  [5] SYSCLKSEC — SYSCLK Clock Selection, STOPWUCK bit, Clock Output on MCO Configuration Security
  [4] LSESEC — LSE Clock Configuration and Status Bits Security
  [3] LSISEC — LSI Clock Configuration and Status Bits Security
  [2] MSISEC — MSI Clock Configuration and Status Bits Security
  [1] HSESEC — HSE Clock Configuration Bits, Status Bits and HSE_CSS Security
  [0] HSISEC — HSI Clock Configuration and Status Bits Security
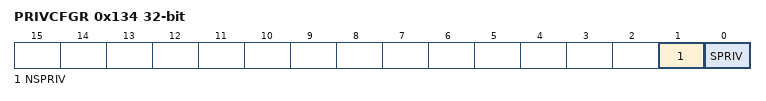
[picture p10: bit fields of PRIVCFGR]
0x134 PRIVCFGR — RCC Privilege Configuration Register
  [1] NSPRIV — RCC Non-Secure Functions Privilege Configuration
  [0] SPRIV — RCC Secure Functions Privilege Configuration
